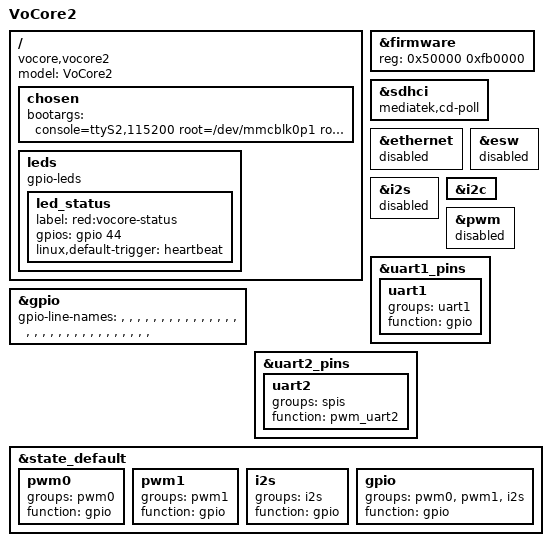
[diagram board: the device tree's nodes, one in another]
#include "mt7628an_vocore_vocore2.dtsi"

#include <dt-bindings/input/input.h>

/ {
	compatible = "vocore,vocore2", "mediatek,mt7628an-soc";
	model = "VoCore2";

	chosen {
		bootargs = "console=ttyS2,115200 root=/dev/mmcblk0p1 rootwait rootdelay=5";
	};

	leds {
		compatible = "gpio-leds";

		led_status {
			label = "red:vocore-status";
			gpios = <&gpio 44 GPIO_ACTIVE_HIGH>;
			linux,default-trigger = "heartbeat";
		};
	};
};

&firmware {
	reg = <0x50000 0xfb0000>;
};

&sdhci {
	status = "okay";
	mediatek,cd-poll;
};

&ethernet {
	status = "disabled";
};

&esw {
	status = "disabled";
};

&i2s {
	status = "disabled";
};

&i2c {
	status = "okay";
};

&pwm {
	status = "disabled";
};

/* Set Names of userspace GPIOS, 4 rows of 8 pins is 32 pins per port. */
&gpio {
		gpio-line-names =  /* 00 - 07 */ "", "", "", "", "", "", "", "",
						   /* 08 - 15 */ "", "", "", "", "", "", "", "",
						   /* 16 - 23 */ "", "", "", "", "", "", "", "",
						   /* 24 - 31 */ "", "", "", "", "", "", "", "";

};

&uart1_pins {
	uart1 {
		groups = "uart1";
		function = "gpio";
	};
};

&uart2_pins {
	uart2 {
		groups = "spis";
		function = "pwm_uart2";
	};
};

&state_default {
	pwm0 {
		groups = "pwm0";
		function = "gpio";
	};

	pwm1 {
		groups = "pwm1";
		function = "gpio";
	};

	i2s {
		groups = "i2s";
		function = "gpio";
	};

	gpio {
		groups = "pwm0", "pwm1", "i2s";
		function = "gpio";
	};
};
